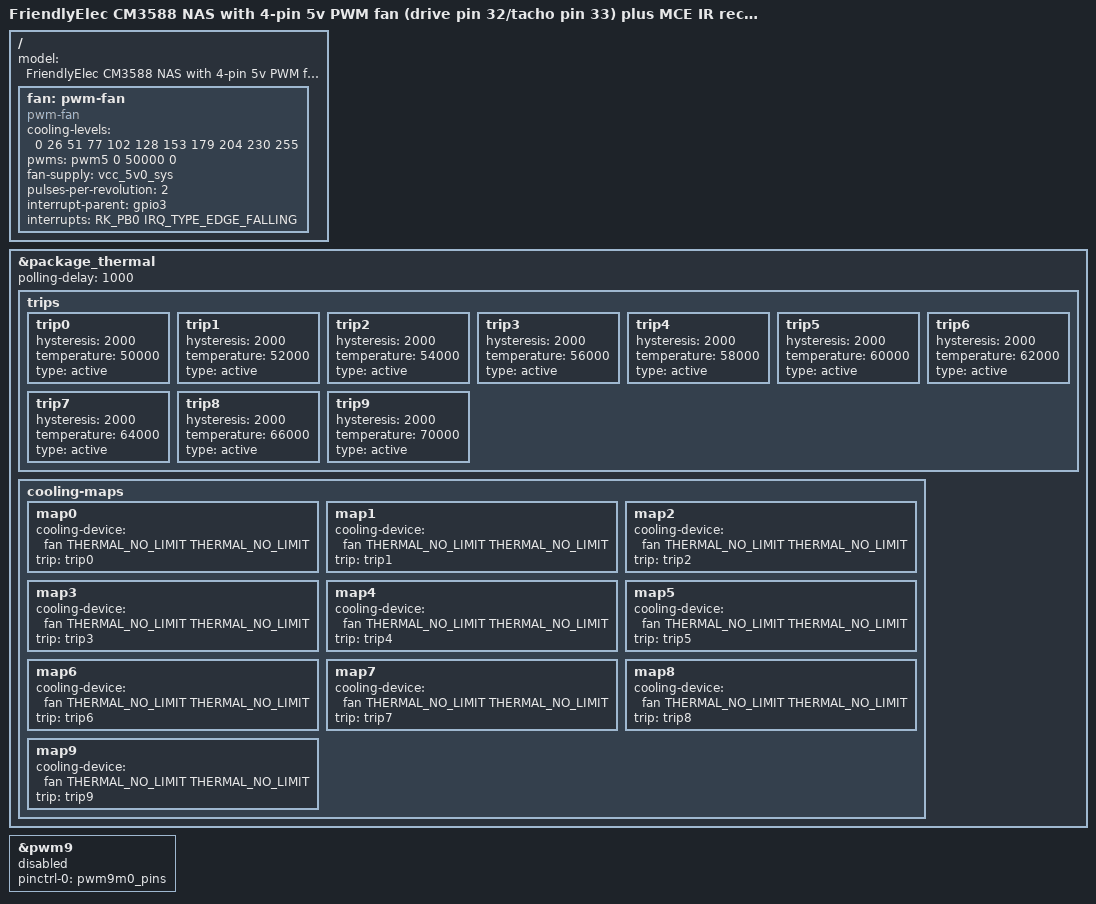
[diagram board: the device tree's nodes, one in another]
// SPDX-License-Identifier: (GPL-2.0+ OR MIT)

/dts-v1/;

#include "rk3588-friendlyelec-cm3588-nas.dts"

/ {
	model = "FriendlyElec CM3588 NAS with 4-pin 5v PWM fan (drive pin 32/tacho pin 33) plus MCE IR receiver";

	fan: pwm-fan {
		compatible = "pwm-fan";
		#cooling-cells = <2>;
		cooling-levels = <0 26 51 77 102 128 153 179 204 230 255>;
		pwms = <&pwm5 0 50000 0>; /* GPIO 40-pin Connector pin 32 - and NOT the original pwm1 which MOSFET-drives the built-in small-connector "5v fan" */
		fan-supply = <&vcc_5v0_sys>;
		pulses-per-revolution = <2>;
		interrupt-parent = <&gpio3>;  /* GPIO GPIO3_B0/PWM9_M0 + ... */
		interrupts = <RK_PB0 IRQ_TYPE_EDGE_FALLING>; /* ... + GPIO 40-pin Connector pin 33 */
		status = "okay";
	};

	// rpardini abusing this for unrelated goodness
	//ir-receiver {
	//	linux,rc-map-name = "rc-rc6-mce";
	//	wakeup-source;
	//};

};

/* Temperature sensor near the center of the SoC */
&package_thermal {
	polling-delay = <1000>;

	trips {
		trip0: trip0 {
			hysteresis = <2000>;
			temperature = <50000>; /* 50 celsius */
			type = "active";
		};
		trip1: trip1 {
			hysteresis = <2000>;
			temperature = <52000>; /* 52 celsius */
			type = "active";
		};
		trip2: trip2 {
			hysteresis = <2000>;
			temperature = <54000>; /* 54 celsius */
			type = "active";
		};
		trip3: trip3 {
			hysteresis = <2000>;
			temperature = <56000>; /* 56 celsius */
			type = "active";
		};
		trip4: trip4 {
			hysteresis = <2000>;
			temperature = <58000>; /* 58 celsius */
			type = "active";
		};
		trip5: trip5 {
			hysteresis = <2000>;
			temperature = <60000>; /* 60 celsius */
			type = "active";
		};
		trip6: trip6 {
			hysteresis = <2000>;
			temperature = <62000>; /* 62 celsius */
			type = "active";
		};
		trip7: trip7 {
			hysteresis = <2000>;
			temperature = <64000>; /* 64 celsius */
			type = "active";
		};
		trip8: trip8 {
			hysteresis = <2000>;
			temperature = <66000>; /* 66 celsius */
			type = "active";
		};
		trip9: trip9 {
			hysteresis = <2000>;
			temperature = <70000>; /* 70 celsius */
			type = "active";
		};
	};

	cooling-maps {
		map0 {
			cooling-device = <&fan THERMAL_NO_LIMIT THERMAL_NO_LIMIT>;
			trip = <&trip0>;
		};
		map1 {
			cooling-device = <&fan THERMAL_NO_LIMIT THERMAL_NO_LIMIT>;
			trip = <&trip1>;
		};
		map2 {
			cooling-device = <&fan THERMAL_NO_LIMIT THERMAL_NO_LIMIT>;
			trip = <&trip2>;
		};
		map3 {
			cooling-device = <&fan THERMAL_NO_LIMIT THERMAL_NO_LIMIT>;
			trip = <&trip3>;
		};
		map4 {
			cooling-device = <&fan THERMAL_NO_LIMIT THERMAL_NO_LIMIT>;
			trip = <&trip4>;
		};
		map5 {
			cooling-device = <&fan THERMAL_NO_LIMIT THERMAL_NO_LIMIT>;
			trip = <&trip5>;
		};
		map6 {
			cooling-device = <&fan THERMAL_NO_LIMIT THERMAL_NO_LIMIT>;
			trip = <&trip6>;
		};
		map7 {
			cooling-device = <&fan THERMAL_NO_LIMIT THERMAL_NO_LIMIT>;
			trip = <&trip7>;
		};
		map8 {
			cooling-device = <&fan THERMAL_NO_LIMIT THERMAL_NO_LIMIT>;
			trip = <&trip8>;
		};
		map9 {
			cooling-device = <&fan THERMAL_NO_LIMIT THERMAL_NO_LIMIT>;
			trip = <&trip9>;
		};
	};
};

/* GPIO 40-pin Connector pin 33 - EXTFAN TACHO - used as interrupt source in pwm-fan - gpio GPIO3_B0/PWM9_M0 */
&pwm9 {
	pinctrl-0 = <&pwm9m0_pins>;
	status = "disabled"; /* unsure if this is enabled or disabled, as it is used as an interrupt source and not pwm output */
};

/* Just for reference, as it is already okay'ed on upstream DT (wasn't on Nargas) */
/* GPIO 40-pin Connector pin 32 - EXTFAN PWM Drive */
/* &pwm5 {
	pinctrl-0 = <&pwm5m1_pins>;
	status = "okay";
};
*/

